# K210 register map
Vendor: Canaan Inc.; File version: 1.0
Registers are 32-bit, read-write, reset 0x0 unless marked. A register's access mark holds for its fields unless they carry their own. Offsets are from the block's base; [hi:lo] are bit positions; lines under a group give offsets from that group; {n}, {i} and the like mark numbered series; 'fields as' and 'values as' point back to an identical list.

## I2C0 — Inter-Integrated Circuit Bus 0
Base 0x50280000
Same registers: I2C1 0x50290000, I2C2 0x502A0000
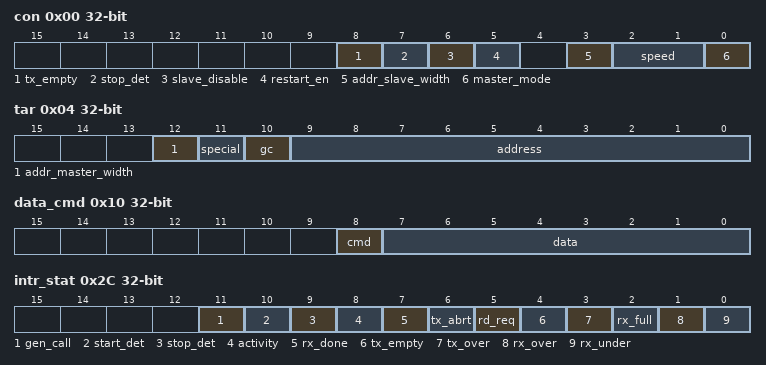
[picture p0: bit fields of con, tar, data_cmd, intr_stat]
0x00 con — Control Register
  [8] tx_empty — TX_EMPTY_CTRL
  [7] stop_det — STOP_DET_IFADDRESSED
  [6] slave_disable — Disable Slave
  [5] restart_en — Enable Restart
  [3] addr_slave_width — Slave address width
    0=b7 (7-bit address); 1=b10 (10-bit address)
  [2:1] speed
    0=standard; 1=fast; 2=highspeed
  [0] master_mode
0x04 tar — Target Address Register
  [12] addr_master_width — Master Address
    0=b7 (7-bit address); 1=b10 (10-bit address)
  [11] special
  [10] gc — GC_OR_START
  [9:0] address — Target Address
0x08 sar — Slave Address Register
  [9:0] address — Slave Address
0x10 data_cmd — Data Buffer and Command Register
  [8] cmd, [7:0] data
0x14 ss_scl_hcnt — Standard Speed Clock SCL High Count Register
  [15:0] count
0x18 ss_scl_lcnt — Standard Speed Clock SCL Low Count Register
  [15:0] count
0x2C intr_stat ro — Interrupt Status Register
  [11] gen_call, [10] start_det, [9] stop_det, [8] activity, [7] rx_done, [6] tx_abrt, [5] rd_req, [4] tx_empty, [3] tx_over, [2] rx_full, [1] rx_over, [0] rx_under
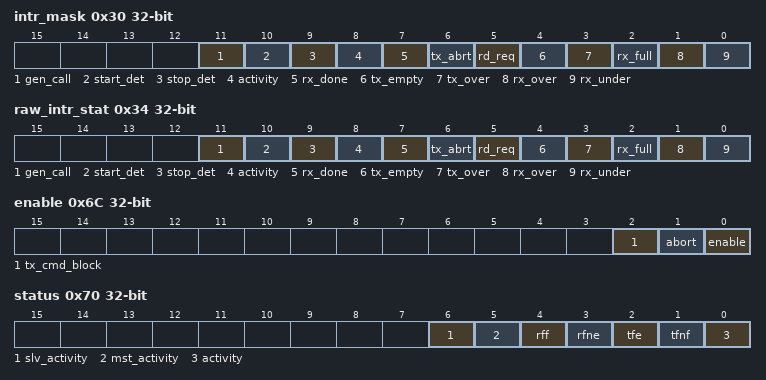
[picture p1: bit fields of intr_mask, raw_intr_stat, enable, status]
0x30 intr_mask — Interrupt Mask Register
  fields as intr_stat
0x34 raw_intr_stat — Raw Interrupt Status Register
  fields as intr_stat
0x38 rx_tl — Receive FIFO Threshold Register
  [2:0] value
0x3C tx_tl — Transmit FIFO Threshold Register
  [2:0] value
0x40 clr_intr ro — Clear Combined and Individual Interrupt Register
  [0] clr
0x44 clr_rx_under ro — Clear RX_UNDER Interrupt Register
  [0] clr
0x48 clr_rx_over ro — Clear RX_OVER Interrupt Register
  [0] clr
0x4C clr_tx_over ro — Clear TX_OVER Interrupt Register
  [0] clr
0x50 clr_rd_req ro — Clear RD_REQ Interrupt Register
  [0] clr
0x54 clr_tx_abrt ro — Clear TX_ABRT Interrupt Register
  [0] clr
0x58 clr_rx_done ro — Clear RX_DONE Interrupt Register
  [0] clr
0x5C clr_activity ro — Clear ACTIVITY Interrupt Register
  [0] clr
0x60 clr_stop_det ro — Clear STOP_DET Interrupt Register
  [0] clr
0x64 clr_start_det ro — Clear START_DET Interrupt Register
  [0] clr
0x68 clr_gen_call ro — I2C Clear GEN_CALL Interrupt Register
  [0] clr
0x6C enable
  [2] tx_cmd_block, [1] abort, [0] enable
0x70 status ro
  [6] slv_activity, [5] mst_activity, [4] rff, [3] rfne, [2] tfe, [1] tfnf, [0] activity
0x74 txflr — Transmit FIFO Level Register
  [2:0] value
0x78 rxflr — Receive FIFO Level Register
  [2:0] value
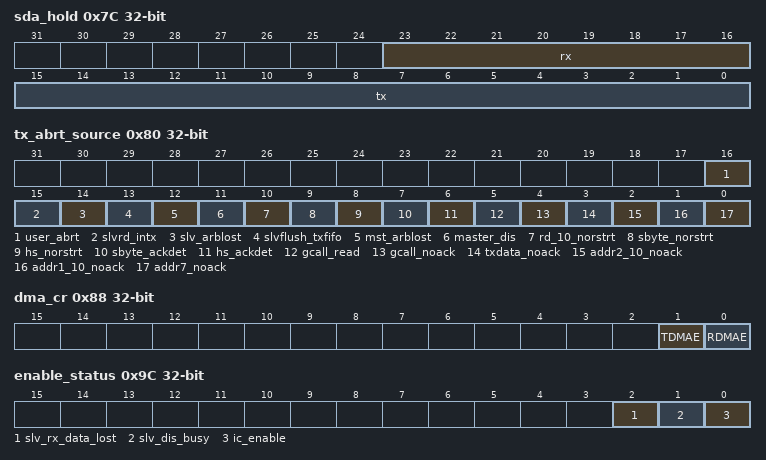
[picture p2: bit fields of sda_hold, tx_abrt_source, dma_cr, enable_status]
0x7C sda_hold — SDA Hold Time Length Register
  [23:16] rx, [15:0] tx
0x80 tx_abrt_source — Transmit Abort Source Register
  [16] user_abrt
  [15] slvrd_intx
  [14] slv_arblost
  [13] slvflush_txfifo
  [12] mst_arblost
  [11] master_dis
  [10] rd_10_norstrt — 10B_RD_NORSTRT
  [9] sbyte_norstrt
  [8] hs_norstrt
  [7] sbyte_ackdet
  [6] hs_ackdet
  [5] gcall_read
  [4] gcall_noack
  [3] txdata_noack
  [2] addr2_10_noack — 10B_ADDR2_NOACK
  [1] addr1_10_noack — 10B_ADDR1_NOACK
  [0] addr7_noack — 7B_ADDR_NOACK
0x88 dma_cr — I2C DMA Control Register
  [1] TDMAE, [0] RDMAE
0x8C dma_tdlr — DMA Transmit Data Level Register
  [2:0] value
0x90 dma_rdlr — DMA Receive Data Level Register
  [2:0] value
0x94 sda_setup
  [7:0] value
0x98 general_call — ACK General Call Register
  [0] call_enable
0x9C enable_status ro
  [2] slv_rx_data_lost, [1] slv_dis_busy, [0] ic_enable
0xA0 fs_spklen — SS, FS or FM+ spike suppression limit
  [7:0] value
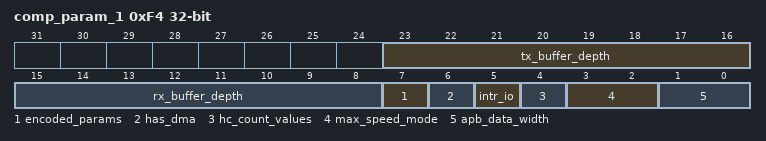
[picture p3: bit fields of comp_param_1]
0xF4 comp_param_1 ro — Component Parameter Register 1
  [23:16] tx_buffer_depth, [15:8] rx_buffer_depth, [7] encoded_params, [6] has_dma, [5] intr_io, [4] hc_count_values, [3:2] max_speed_mode, [1:0] apb_data_width
0xF8 comp_version ro — Component Version Register
  [31:0] value
0xFC comp_type ro — Component Type Register
  [31:0] value

## FPIOA — Field Programmable IO Array
Base 0x502B0000
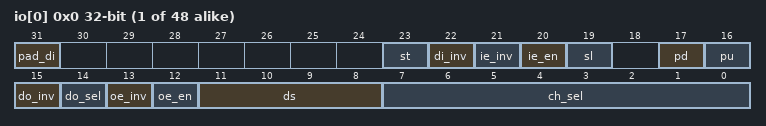
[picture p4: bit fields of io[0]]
{0x0+4i} io[{i}] (i=0..47) — FPIOA GPIO multiplexer io array
  [31] pad_di — Read current IO's data input
  [23] st — Schmitt trigger
  [22] di_inv — Invert Data input
  [21] ie_inv — Invert input enable
  [20] ie_en — Static input enable, will AND with IE_INV
  [19] sl — Slew rate control enable
  [17] pd — Pull down enable. 0 for nothing, 1 for pull down
  [16] pu — Pull up enable. 0 for nothing, 1 for pull up
  [15] do_inv — Invert the result of data output select (DO_SEL)
  [14] do_sel — Data output select: 0 for DO, 1 for OE
  [13] oe_inv — Invert output enable
  [12] oe_en — Static output enable, will AND with OE_INV
  [11:8] ds — Driving selector
  [7:0] ch_sel — Channel select from 256 input
{0xC0+4i} tie_en[{i}] (i=0..7) — FPIOA GPIO multiplexer tie enable array
{0xE0+4i} tie_val[{i}] (i=0..7) — FPIOA GPIO multiplexer tie value array

## TIMER0
Base 0x502D0000
Same registers: TIMER1 0x502E0000, TIMER2 0x502F0000
{0x0+0x14*i} channel{i} (i=0..3) group — Channel cluster: load_count, current_value, control, eoi and intr_stat registers
  0x00 load_count
  0x04 current_value
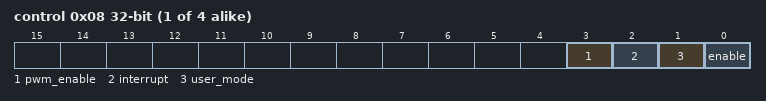
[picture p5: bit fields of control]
  0x08 control
    [3] pwm_enable
    [2] interrupt — INTERRUPT_MASK
    [1] user_mode
    [0] enable
  0x0C eoi — Interrupt Clear Register
  0x10 intr_stat — Interrupt Status Register
0xA0 intr_stat — Interrupt Status Register
0xA4 eoi — Interrupt Clear Register
0xA8 raw_intr_stat — Raw Interrupt Status Register
0xAC comp_version — Component Version Register
{0xB0+4i} load_count2{i} (i=0..3)
